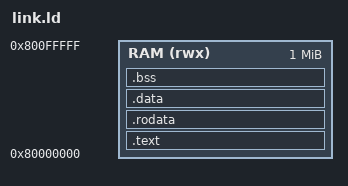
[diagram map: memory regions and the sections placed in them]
/* Memory layout of the emulated machine (see src/machine.ts). */
OUTPUT_ARCH(riscv)
ENTRY(_start)

MEMORY
{
    RAM (rwx) : ORIGIN = 0x80000000, LENGTH = 1M
}

SECTIONS
{
    .text : {
        KEEP(*(.text.start))
        *(.text .text.*)
    } > RAM

    .rodata : { *(.rodata .rodata.* .srodata .srodata.*) } > RAM

    .data : {
        __global_pointer$ = . + 0x800;
        *(.data .data.* .sdata .sdata.*)
    } > RAM

    .bss (NOLOAD) : ALIGN(4) {
        __bss_start = .;
        *(.bss .bss.* .sbss .sbss.* COMMON)
        . = ALIGN(4);
        __bss_end = .;
    } > RAM

    __stack_top = ORIGIN(RAM) + LENGTH(RAM);
}
